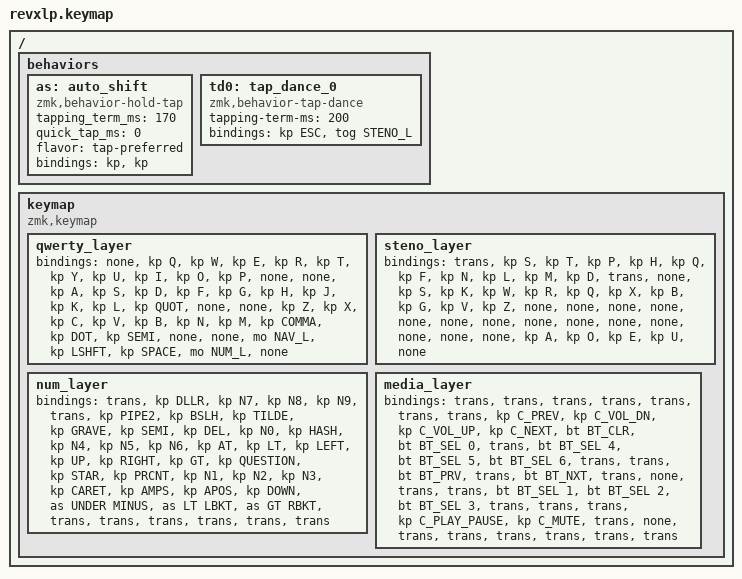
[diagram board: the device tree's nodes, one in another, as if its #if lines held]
/*
 * Copyright (c) 2020 The ZMK Contributors
 *
 * SPDX-License-Identifier: MIT
 */

#include <behaviors.dtsi>
#include <dt-bindings/zmk/keys.h>
#include <dt-bindings/zmk/bt.h>
#include <dt-bindings/zmk/backlight.h>

#define AS(keycode) &as LS(keycode) keycode     // Autoshift Macro

#define STENO_L 1
#define NUM_L 2
#define MED_L 3

/ {
    behaviors {
        as: auto_shift {
            compatible = "zmk,behavior-hold-tap";
            #binding-cells = <2>;
            tapping_term_ms = <170>;
            quick_tap_ms = <0>;
            flavor = "tap-preferred";
            bindings = <&kp>, <&kp>;
        };
        td0: tap_dance_0 {
            compatible = "zmk,behavior-tap-dance";
            #binding-cells = <0>;
            tapping-term-ms = <200>;
            bindings = <&kp ESC>, <&tog STENO_L>;
        };
    };



    keymap {
        compatible = "zmk,keymap";

#ifdef QWERTY_BASE
        qwerty_layer {
            bindings = <
       &none        &kp Q      &kp W      &kp E       &kp R          &kp T         &kp Y            &kp U          &kp I       &kp O      &kp P    &none
       &none        &kp A      &kp S      &kp D       &kp F          &kp G         &kp H            &kp J          &kp K       &kp L      &kp QUOT &none
       &none        &kp Z      &kp X      &kp C       &kp V          &kp B         &kp N            &kp M          &kp COMMA   &kp DOT    &kp SEMI &none
                                          &none   &mo NAV_L      &kp LSHFT      &kp SPACE  &mo NUM_L &none
            >;
        };
#else
        colemak_dhm_layer {
            bindings = <
       &td0               AS(Q)      AS(W)      AS(F)       AS(P)          AS(B)         AS(J)            AS(L)          AS(U)       AS(Y)      &kp COLON &kp BKSP
       &kp TAB            AS(A)      AS(R)      AS(S)       AS(T)          AS(G)         AS(M)            AS(N)          AS(E)       AS(I)      AS(O)     &kp SLASH
       &lt MED_L PLUS     AS(Z)      AS(X)      AS(C)       AS(D)          AS(V)         AS(K)            AS(H)          &kp LBRC    &kp RBRC   &kp LPAR  &kp RPAR
                                          &lt NUM_L DQT    &mt LCTRL EQUAL      &mt LSHFT SPACE      &mt RSHFT ENTER        &mt RCTRL DOT       &mt RALT COMMA
            >;
        };
#endif

        steno_layer {
            bindings = <
       &trans        &kp S    &kp T     &kp P      &kp H          &kp Q       &kp F        &kp N       &kp L   &kp M   &kp D &trans
       &none         &kp S    &kp K     &kp W      &kp R          &kp Q       &kp X        &kp B       &kp G   &kp V   &kp Z &none
       &none         &none     &none    &none      &none          &none          &none        &none       &none   &none  &none &none
                                           &none  &kp A          &kp O       &kp E          &kp U &none
            >;
        };

        num_layer {
            bindings = <
       &trans        &kp DLLR   &kp N7     &kp N8      &kp N9          &trans        &kp PIPE2      &kp BSLH       &kp TILDE      &kp GRAVE       &kp SEMI  &kp DEL
       &kp N0        &kp HASH   &kp N4     &kp N5      &kp N6          &kp AT        &kp LT        &kp LEFT       &kp UP         &kp RIGHT       &kp GT    &kp QUESTION
       &kp STAR      &kp PRCNT  &kp N1     &kp N2      &kp N3          &kp CARET     &kp AMPS      &kp APOS       &kp DOWN       &as UNDER MINUS  &as LT LBKT   &as GT RBKT
                                          &trans   &trans          &trans       &trans        &trans &trans
            >;
        };

        media_layer {
            bindings = <
       &trans        &trans     &trans           &trans            &trans                &trans       &trans           &kp C_PREV     &kp C_VOL_DN     &kp C_VOL_UP &kp C_NEXT &bt BT_CLR
       &bt BT_SEL 0  &trans     &bt BT_SEL 4     &bt BT_SEL 5      &bt BT_SEL 6          &trans       &trans           &bt BT_PRV     &trans           &bt BT_NXT   &trans     &none
       &trans        &trans     &bt BT_SEL 1     &bt BT_SEL 2      &bt BT_SEL 3          &trans       &trans           &trans         &kp C_PLAY_PAUSE &kp C_MUTE   &trans     &none
                                           &trans  &trans          &trans       &trans           &trans &trans
            >;
        };
    };
};
